# COMPUTE_CLUSTER_J7AHP0_DRU_0_MMR_DRU4_MMR_CFG_DRU_UTLB register map
Vendor: Texas Instruments
Peripheral module from a debugger description file (folder J7_AHP).
Registers are 64-bit, access per field, reset 0x0 unless marked. A register's access mark holds for its fields unless they carry their own. Offsets are as the file gives them; lines under a group give offsets from that group; [hi:lo] are bit positions; {n}, {i} and the like mark numbered series; 'fields as' and 'values as' point back to an identical list; <NAME> marks a mode.

## COMPUTE_CLUSTER_J7AHP0_DRU_0_MMR_DRU4_MMR_CFG_DRU_UTLB
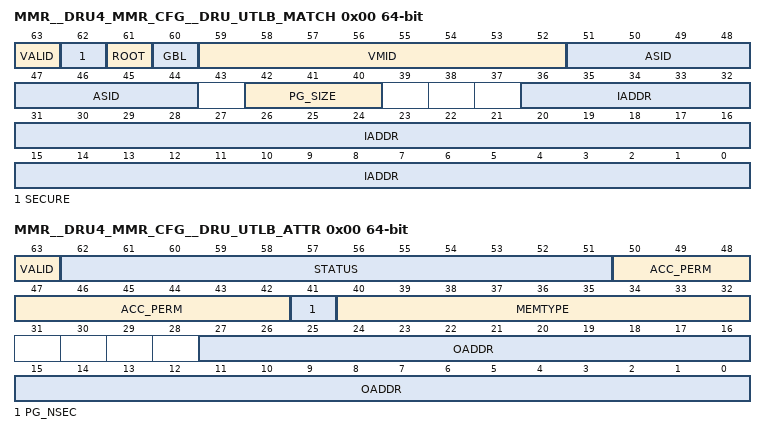
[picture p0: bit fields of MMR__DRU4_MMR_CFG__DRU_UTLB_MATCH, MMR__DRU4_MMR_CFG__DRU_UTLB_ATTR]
0x00 MMR__DRU4_MMR_CFG__DRU_UTLB_MATCH
  [63] VALID rw — Entry Valid
  [62] SECURE rw — Secure Page
  [61] ROOT rw — Root Page
  [60] GBL rw — Global Page
  [59:52] VMID rw
  [51:44] ASID rw
  [42:40] PG_SIZE rw — Page Size
  [36:0] IADDR rw — Input Address
0x00 MMR__DRU4_MMR_CFG__DRU_UTLB_ATTR
  [63] VALID rw — Entry Valid
  [62:51] STATUS rw — TLB Status
  [50:42] ACC_PERM rw — Access Permissions
  [41] PG_NSEC rw — Page Non-Secure
  [40:32] MEMTYPE rw — Page Memory Type
  [27:0] OADDR rw — Output Address
0x00 MMR__DRU4_MMR_CFG__DRU_UTLB_MATCH
  fields as MMR__DRU4_MMR_CFG__DRU_UTLB_MATCH
0x00 MMR__DRU4_MMR_CFG__DRU_UTLB_ATTR
  fields as MMR__DRU4_MMR_CFG__DRU_UTLB_ATTR
